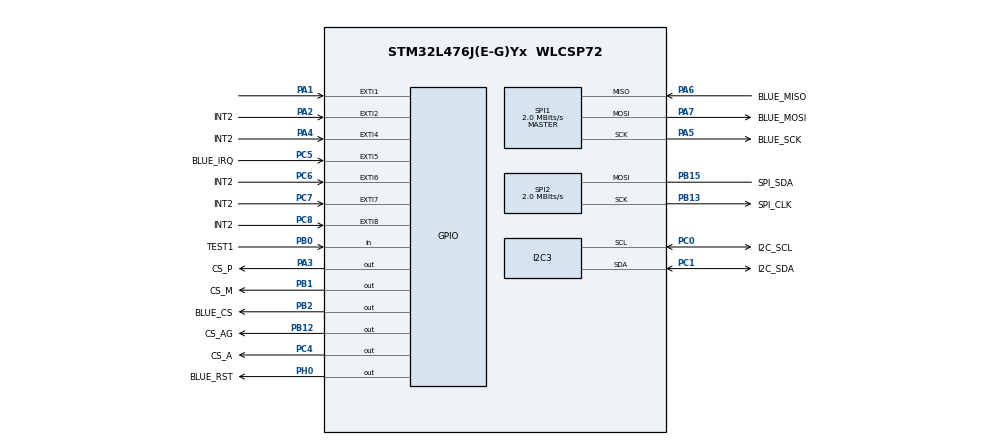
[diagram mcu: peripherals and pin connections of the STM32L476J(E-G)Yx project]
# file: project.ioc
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FREERTOS.Mutexes01=mutex_spi1,Dynamic,NULL;mutex_spi2,Dynamic,NULL;mutex_spi3,Dynamic,NULL;mutex_i2c1,Dynamic,NULL;mutex_i2c2,Dynamic,NULL;mutex_i2c3,Dynamic,NULL
FREERTOS.Tasks01=defaultTask,0,128,StartDefaultTask,Default,NULL
FREERTOS.configUSE_RECURSIVE_MUTEXES=0
Mcu.Family=STM32L4
Mcu.Name=STM32L476J(E-G)Yx
Mcu.Package=WLCSP72
NVIC.PriorityGroup=NVIC_PRIORITYGROUP_4
NVIC.TIM1_UP_TIM16_IRQn=true\:0\:0\:false\:false\:true\:false\:false
NVIC.TimeBase=TIM1_UP_TIM16_IRQn
NVIC.TimeBaseIP=TIM1
PA1.Signal=GPXTI1
PA2.GPIO_Label=INT2
PA2.Signal=GPXTI2
PA3.GPIO_Label=CS_P
PA3.Signal=GPIO_Output
PA4.GPIO_Label=INT2
PA4.Signal=GPXTI4
PA5.GPIO_Label=BLUE_SCK
PA5.Mode=Full_Duplex_Master
PA5.Signal=SPI1_SCK
PA6.GPIO_Label=BLUE_MISO
PA6.Mode=Full_Duplex_Master
PA6.Signal=SPI1_MISO
PA7.GPIO_Label=BLUE_MOSI
PA7.Mode=Full_Duplex_Master
PA7.Signal=SPI1_MOSI
PB0.GPIO_Label=TEST1
PB0.Signal=GPIO_Input
PB1.GPIO_Label=CS_M
PB1.Signal=GPIO_Output
PB12.GPIO_Label=CS_AG
PB12.Signal=GPIO_Output
PB13.GPIO_Label=SPI_CLK
PB13.Mode=Simplex_Bidirectional_Master
PB13.Signal=SPI2_SCK
PB15.GPIO_Label=SPI_SDA
PB15.Mode=Simplex_Bidirectional_Master
PB15.Signal=SPI2_MOSI
PB2.GPIO_Label=BLUE_CS
PB2.Signal=GPIO_Output
PC0.GPIO_Label=I2C_SCL
PC0.Mode=I2C
PC0.Signal=I2C3_SCL
PC1.GPIO_Label=I2C_SDA
PC1.Mode=I2C
PC1.Signal=I2C3_SDA
PC4.GPIO_Label=CS_A
PC4.Signal=GPIO_Output
PC5.GPIO_Label=BLUE_IRQ
PC5.Signal=GPXTI5
PC6.GPIO_Label=INT2
PC6.Signal=GPXTI6
PC7.GPIO_Label=INT2
PC7.Signal=GPXTI7
PC8.GPIO_Label=INT2
PC8.Signal=GPXTI8
PH0-OSC_IN\ (PH0).GPIO_Label=BLUE_RST
PH0-OSC_IN\ (PH0).Signal=GPIO_Output
ProjectManager.HeapSize=0x200
ProjectManager.StackSize=0x400
ProjectManager.TargetToolchain=EWARM
RCC.HSE_VALUE=8000000
RCC.HSI_VALUE=16000000
RCC.LSE_VALUE=32768
RCC.MSI_VALUE=4000000
RCC.VCOOutputFreq_Value=32000000
SPI1.CalculateBaudRate=2.0 MBits/s
SPI1.Direction=SPI_DIRECTION_2LINES
SPI1.Mode=SPI_MODE_MASTER
SPI1.VirtualType=VM_MASTER
SPI2.CalculateBaudRate=2.0 MBits/s
SPI2.Direction=SPI_DIRECTION_1LINE
SPI2.Mode=SPI_MODE_MASTER
SPI2.VirtualType=VM_MASTER
VP_FREERTOS_VS_ENABLE.Mode=Enabled
VP_SYS_VS_tim1.Mode=TIM1
board=project

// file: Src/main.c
/**
  ******************************************************************************
  * @file           : main.c
  * @brief          : Main program body
  ******************************************************************************
  * This notice applies to any and all portions of this file
  * that are not between comment pairs USER CODE BEGIN and
  * USER CODE END. Other portions of this file, whether
  * inserted by the user or by software development tools
  * are owned by their respective copyright owners.
  *
  * Copyright (c) 2018 STMicroelectronics International N.V.
  * All rights reserved.
  *
  * Redistribution and use in source and binary forms, with or without
  * modification, are permitted, provided that the following conditions are met:
  *
  * 1. Redistribution of source code must retain the above copyright notice,
  *    this list of conditions and the following disclaimer.
  * 2. Redistributions in binary form must reproduce the above copyright notice,
  *    this list of conditions and the following disclaimer in the documentation
  *    and/or other materials provided with the distribution.
  * 3. Neither the name of STMicroelectronics nor the names of other
  *    contributors to this software may be used to endorse or promote products
  *    derived from this software without specific written permission.
  * 4. This software, including modifications and/or derivative works of this
  *    software, must execute solely and exclusively on microcontroller or
  *    microprocessor devices manufactured by or for STMicroelectronics.
  * 5. Redistribution and use of this software other than as permitted under
  *    this license is void and will automatically terminate your rights under
  *    this license.
  *
  * THIS SOFTWARE IS PROVIDED BY STMICROELECTRONICS AND CONTRIBUTORS "AS IS"
  * AND ANY EXPRESS, IMPLIED OR STATUTORY WARRANTIES, INCLUDING, BUT NOT
  * LIMITED TO, THE IMPLIED WARRANTIES OF MERCHANTABILITY, FITNESS FOR A
  * PARTICULAR PURPOSE AND NON-INFRINGEMENT OF THIRD PARTY INTELLECTUAL PROPERTY
  * RIGHTS ARE DISCLAIMED TO THE FULLEST EXTENT PERMITTED BY LAW. IN NO EVENT
  * SHALL STMICROELECTRONICS OR CONTRIBUTORS BE LIABLE FOR ANY DIRECT, INDIRECT,
  * INCIDENTAL, SPECIAL, EXEMPLARY, OR CONSEQUENTIAL DAMAGES (INCLUDING, BUT NOT
  * LIMITED TO, PROCUREMENT OF SUBSTITUTE GOODS OR SERVICES; LOSS OF USE, DATA,
  * OR PROFITS; OR BUSINESS INTERRUPTION) HOWEVER CAUSED AND ON ANY THEORY OF
  * LIABILITY, WHETHER IN CONTRACT, STRICT LIABILITY, OR TORT (INCLUDING
  * NEGLIGENCE OR OTHERWISE) ARISING IN ANY WAY OUT OF THE USE OF THIS SOFTWARE,
  * EVEN IF ADVISED OF THE POSSIBILITY OF SUCH DAMAGE.
  *
  ******************************************************************************
  */
#include "main.h"
#include "stm32l4xx_hal.h"
#include "cmsis_os.h"
#include "i2c.h"
#include "spi.h"
#include "gpio.h"

/* USER CODE BEGIN PV */
/* Private variables ---------------------------------------------------------*/

/* USER CODE END PV */

void SystemClock_Config(void);
void MX_FREERTOS_Init(void);

/* USER CODE BEGIN PFP */
/* Private function prototypes -----------------------------------------------*/

/* USER CODE END PFP */

int main(void)
{

  /* MCU Configuration----------------------------------------------------------*/

  /* Reset of all peripherals, Initializes the Flash interface and the Systick. */
  HAL_Init();

  /* Configure the system clock */
  SystemClock_Config();

  /* Initialize all configured peripherals */
  MX_GPIO_Init();
  MX_SPI2_Init();
  MX_SPI1_Init();
  MX_I2C3_Init();
  /* USER CODE BEGIN 2 */

  //LSM6DSL_G_Init( DrvContextTypeDef *handle );

  /* USER CODE END 2 */

  /* Call init function for freertos objects (in freertos.c) */
  MX_FREERTOS_Init();

  /* Start scheduler */
  osKernelStart();

  /* We should never get here as control is now taken by the scheduler */

  /* Infinite loop */
  while (1)
  {

  }

}

void SystemClock_Config(void)
{

  RCC_OscInitTypeDef RCC_OscInitStruct;
  RCC_ClkInitTypeDef RCC_ClkInitStruct;
  RCC_PeriphCLKInitTypeDef PeriphClkInit;

    /**Initializes the CPU, AHB and APB busses clocks
    */
  RCC_OscInitStruct.OscillatorType = RCC_OSCILLATORTYPE_MSI;
  RCC_OscInitStruct.MSIState = RCC_MSI_ON;
  RCC_OscInitStruct.MSICalibrationValue = 0;
  RCC_OscInitStruct.MSIClockRange = RCC_MSIRANGE_6;
  RCC_OscInitStruct.PLL.PLLState = RCC_PLL_NONE;
  if (HAL_RCC_OscConfig(&RCC_OscInitStruct) != HAL_OK)
  {
    _Error_Handler(__FILE__, __LINE__);
  }

    /**Initializes the CPU, AHB and APB busses clocks
    */
  RCC_ClkInitStruct.ClockType = RCC_CLOCKTYPE_HCLK|RCC_CLOCKTYPE_SYSCLK
                              |RCC_CLOCKTYPE_PCLK1|RCC_CLOCKTYPE_PCLK2;
  RCC_ClkInitStruct.SYSCLKSource = RCC_SYSCLKSOURCE_MSI;
  RCC_ClkInitStruct.AHBCLKDivider = RCC_SYSCLK_DIV1;
  RCC_ClkInitStruct.APB1CLKDivider = RCC_HCLK_DIV1;
  RCC_ClkInitStruct.APB2CLKDivider = RCC_HCLK_DIV1;

  if (HAL_RCC_ClockConfig(&RCC_ClkInitStruct, FLASH_LATENCY_0) != HAL_OK)
  {
    _Error_Handler(__FILE__, __LINE__);
  }

  PeriphClkInit.PeriphClockSelection = RCC_PERIPHCLK_I2C3;
  PeriphClkInit.I2c3ClockSelection = RCC_I2C3CLKSOURCE_PCLK1;
  if (HAL_RCCEx_PeriphCLKConfig(&PeriphClkInit) != HAL_OK)
  {
    _Error_Handler(__FILE__, __LINE__);
  }

    /**Configure the main internal regulator output voltage
    */
  if (HAL_PWREx_ControlVoltageScaling(PWR_REGULATOR_VOLTAGE_SCALE1) != HAL_OK)
  {
    _Error_Handler(__FILE__, __LINE__);
  }

    /**Configure the Systick interrupt time
    */
  HAL_SYSTICK_Config(HAL_RCC_GetHCLKFreq()/1000);

    /**Configure the Systick
    */
  HAL_SYSTICK_CLKSourceConfig(SYSTICK_CLKSOURCE_HCLK);

  /* SysTick_IRQn interrupt configuration */
  HAL_NVIC_SetPriority(SysTick_IRQn, 15, 0);
}

void HAL_TIM_PeriodElapsedCallback(TIM_HandleTypeDef *htim)
{
  if (htim->Instance == TIM1) {
    HAL_IncTick();
  }
}

void _Error_Handler(char *file, int line)
{
  while(1)
  {
  }
}

/************************ (C) COPYRIGHT STMicroelectronics *****END OF FILE****/

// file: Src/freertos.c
/**
  ******************************************************************************
  * File Name          : freertos.c
  * Description        : Code for freertos applications
  ******************************************************************************
  * This notice applies to any and all portions of this file
  * that are not between comment pairs USER CODE BEGIN and
  * USER CODE END. Other portions of this file, whether
  * inserted by the user or by software development tools
  * are owned by their respective copyright owners.
  *
  * Copyright (c) 2018 STMicroelectronics International N.V.
  * All rights reserved.
  *
  * Redistribution and use in source and binary forms, with or without
  * modification, are permitted, provided that the following conditions are met:
  *
  * 1. Redistribution of source code must retain the above copyright notice,
  *    this list of conditions and the following disclaimer.
  * 2. Redistributions in binary form must reproduce the above copyright notice,
  *    this list of conditions and the following disclaimer in the documentation
  *    and/or other materials provided with the distribution.
  * 3. Neither the name of STMicroelectronics nor the names of other
  *    contributors to this software may be used to endorse or promote products
  *    derived from this software without specific written permission.
  * 4. This software, including modifications and/or derivative works of this
  *    software, must execute solely and exclusively on microcontroller or
  *    microprocessor devices manufactured by or for STMicroelectronics.
  * 5. Redistribution and use of this software other than as permitted under
  *    this license is void and will automatically terminate your rights under
  *    this license.
  *
  * THIS SOFTWARE IS PROVIDED BY STMICROELECTRONICS AND CONTRIBUTORS "AS IS"
  * AND ANY EXPRESS, IMPLIED OR STATUTORY WARRANTIES, INCLUDING, BUT NOT
  * LIMITED TO, THE IMPLIED WARRANTIES OF MERCHANTABILITY, FITNESS FOR A
  * PARTICULAR PURPOSE AND NON-INFRINGEMENT OF THIRD PARTY INTELLECTUAL PROPERTY
  * RIGHTS ARE DISCLAIMED TO THE FULLEST EXTENT PERMITTED BY LAW. IN NO EVENT
  * SHALL STMICROELECTRONICS OR CONTRIBUTORS BE LIABLE FOR ANY DIRECT, INDIRECT,
  * INCIDENTAL, SPECIAL, EXEMPLARY, OR CONSEQUENTIAL DAMAGES (INCLUDING, BUT NOT
  * LIMITED TO, PROCUREMENT OF SUBSTITUTE GOODS OR SERVICES; LOSS OF USE, DATA,
  * OR PROFITS; OR BUSINESS INTERRUPTION) HOWEVER CAUSED AND ON ANY THEORY OF
  * LIABILITY, WHETHER IN CONTRACT, STRICT LIABILITY, OR TORT (INCLUDING
  * NEGLIGENCE OR OTHERWISE) ARISING IN ANY WAY OUT OF THE USE OF THIS SOFTWARE,
  * EVEN IF ADVISED OF THE POSSIBILITY OF SUCH DAMAGE.
  *
  ******************************************************************************
  */

#include "FreeRTOS.h"
#include "task.h"
#include "cmsis_os.h"

osThreadId defaultTaskHandle;
osMutexId mutex_spi1Handle;
osMutexId mutex_spi2Handle;
osMutexId mutex_spi3Handle;
osMutexId mutex_i2c1Handle;
osMutexId mutex_i2c2Handle;
osMutexId mutex_i2c3Handle;

void StartDefaultTask(void const * argument);

void MX_FREERTOS_Init(void); /* (MISRA C 2004 rule 8.1) */

/* Hook prototypes */

/* Init FreeRTOS */

void MX_FREERTOS_Init(void) {

  /* Create the mutex(es) */
  /* definition and creation of mutex_spi1 */
  osMutexDef(mutex_spi1);
  mutex_spi1Handle = osMutexCreate(osMutex(mutex_spi1));

  /* definition and creation of mutex_spi2 */
  osMutexDef(mutex_spi2);
  mutex_spi2Handle = osMutexCreate(osMutex(mutex_spi2));

  /* definition and creation of mutex_spi3 */
  osMutexDef(mutex_spi3);
  mutex_spi3Handle = osMutexCreate(osMutex(mutex_spi3));

  /* definition and creation of mutex_i2c1 */
  osMutexDef(mutex_i2c1);
  mutex_i2c1Handle = osMutexCreate(osMutex(mutex_i2c1));

  /* definition and creation of mutex_i2c2 */
  osMutexDef(mutex_i2c2);
  mutex_i2c2Handle = osMutexCreate(osMutex(mutex_i2c2));

  /* definition and creation of mutex_i2c3 */
  osMutexDef(mutex_i2c3);
  mutex_i2c3Handle = osMutexCreate(osMutex(mutex_i2c3));

  /* Create the thread(s) */
  /* definition and creation of defaultTask */
  osThreadDef(defaultTask, StartDefaultTask, osPriorityNormal, 0, 128);
  defaultTaskHandle = osThreadCreate(osThread(defaultTask), NULL);

}

/* StartDefaultTask function */
void StartDefaultTask(void const * argument)
{

  for(;;)
  {
    osDelay(1);
  }
}

/************************ (C) COPYRIGHT STMicroelectronics *****END OF FILE****/
